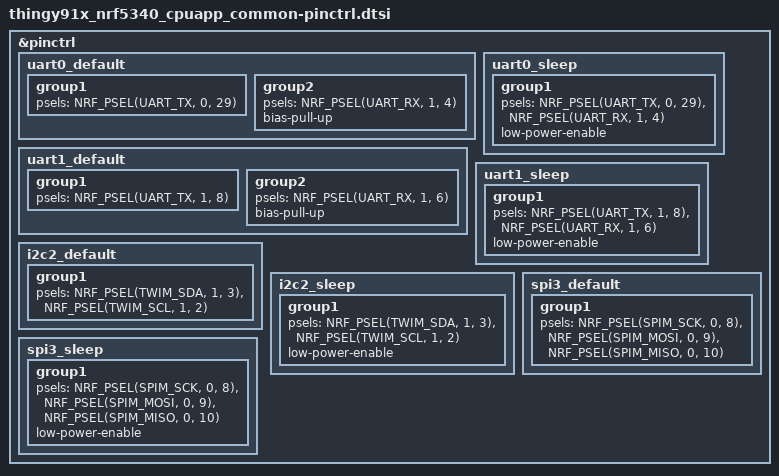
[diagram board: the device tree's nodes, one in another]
/*
 * Copyright (c) 2024 Nordic Semiconductor
 * SPDX-License-Identifier: LicenseRef-Nordic-5-Clause
 */

&pinctrl {
	uart0_default: uart0_default {
		group1 {
			psels = <NRF_PSEL(UART_TX, 0, 29)>;
		};
		group2 {
			psels = <NRF_PSEL(UART_RX, 1, 4)>;
			bias-pull-up;
		};
	};

	uart0_sleep: uart0_sleep {
		group1 {
			psels = <NRF_PSEL(UART_TX, 0, 29)>,
				<NRF_PSEL(UART_RX, 1, 4)>;
			low-power-enable;
		};
	};

	uart1_default: uart1_default {
		group1 {
			psels = <NRF_PSEL(UART_TX, 1, 8)>;
		};
		group2 {
			psels = <NRF_PSEL(UART_RX, 1, 6)>;
			bias-pull-up;
		};
	};

	uart1_sleep: uart1_sleep {
		group1 {
			psels = <NRF_PSEL(UART_TX, 1, 8)>,
				<NRF_PSEL(UART_RX, 1, 6)>;
			low-power-enable;
		};
	};
	i2c2_default: i2c2_default {
		group1 {
			psels = <NRF_PSEL(TWIM_SDA, 1, 3)>,
				<NRF_PSEL(TWIM_SCL, 1, 2)>;
		};
	};

	i2c2_sleep: i2c2_sleep {
		group1 {
			psels = <NRF_PSEL(TWIM_SDA, 1, 3)>,
				<NRF_PSEL(TWIM_SCL, 1, 2)>;
			low-power-enable;
		};
	};

	spi3_default: spi3_default {
		group1 {
			psels = <NRF_PSEL(SPIM_SCK, 0, 8)>,
				<NRF_PSEL(SPIM_MOSI, 0, 9)>,
				<NRF_PSEL(SPIM_MISO, 0, 10)>;
		};
	};

	spi3_sleep: spi3_sleep {
		group1 {
			psels = <NRF_PSEL(SPIM_SCK, 0, 8)>,
				<NRF_PSEL(SPIM_MOSI, 0, 9)>,
				<NRF_PSEL(SPIM_MISO, 0, 10)>;
			low-power-enable;
		};
	};
};
